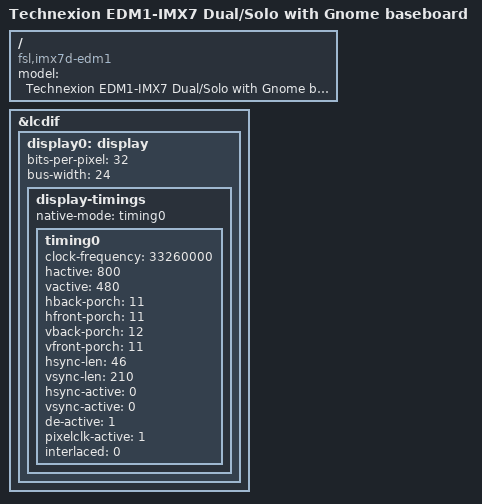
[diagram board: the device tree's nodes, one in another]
/*
 * Copyright 2018 TechNexion Ltd.
 *
 * Author: Tapani Utriainen <tapani@technexion.com>
 *         Richard Hu <richard.hu@technexion.com>
 *         Ray Chang <ray.chang@technexion.com>
 *
 * This program is free software; you can redistribute it and/or modify
 * it under the terms of the GNU General Public License version 2 as
 * published by the Free Software Foundation.
 *
 */
/dts-v1/;

#include "imx7d.dtsi"
#include "imx7d-edm1-qca.dtsi"
#include "baseboard_edm1_gnome.dtsi"

/ {
	model = "Technexion EDM1-IMX7 Dual/Solo with Gnome baseboard";
	compatible = "fsl,imx7d-edm1", "fsl,imx7d";
};

&lcdif {
	status = "okay";

	display0: display {
		bits-per-pixel = <32>;
		bus-width = <24>;

		display-timings {
			native-mode = <&timing0>;
			timing0: timing0 {
				clock-frequency = <33260000>;
				hactive = <800>;
				vactive = <480>;
				hback-porch = <11>;
				hfront-porch = <11>;
				vback-porch = <12>;
				vfront-porch = <11>;
				hsync-len = <46>;
				vsync-len = <210>;
				hsync-active = <0>;
				vsync-active = <0>;
				de-active = <1>;
				pixelclk-active = <1>;
				interlaced =  <0>;
			};
		};
	};
};
